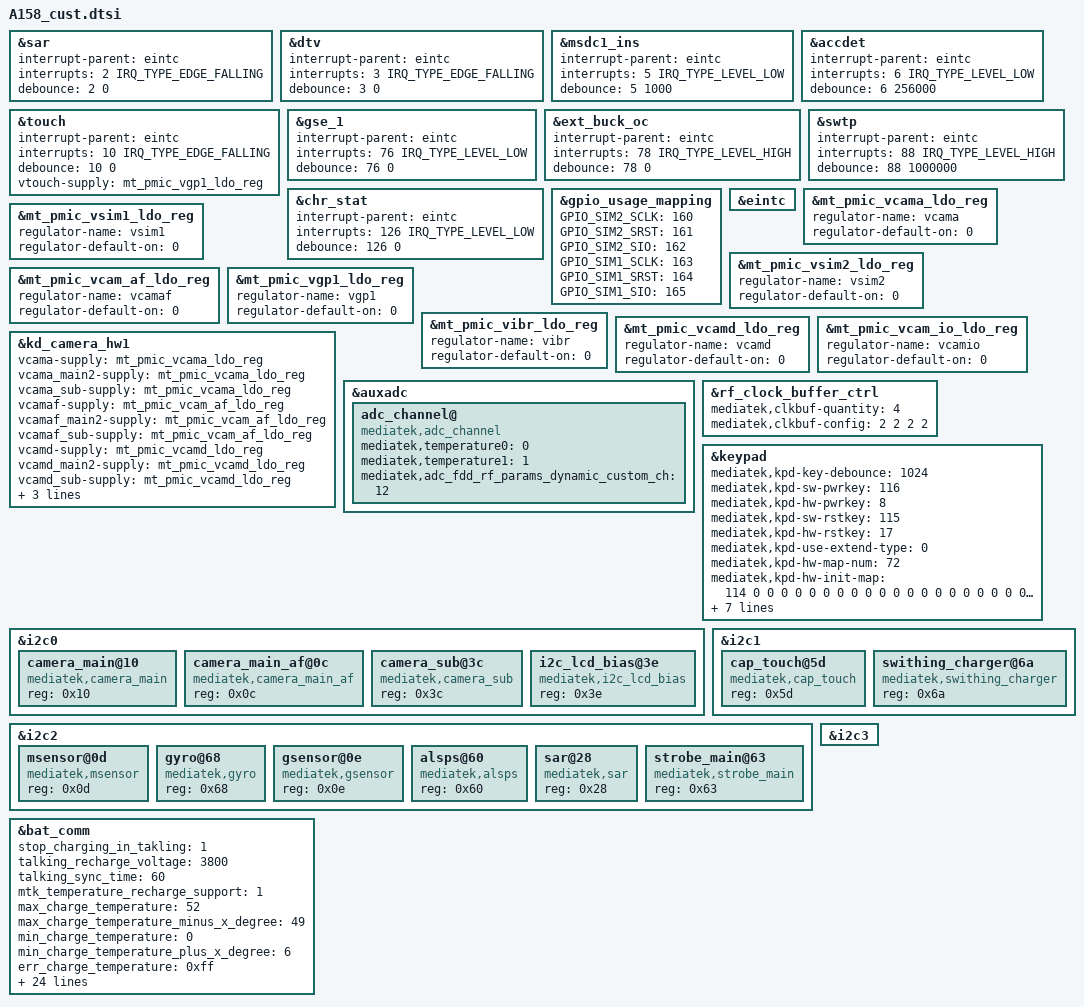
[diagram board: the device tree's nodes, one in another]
/*
 * Generated by MTK SP Drv_CodeGen Version 03.13.6  for MT6735M. Copyright MediaTek Inc. (C) 2013.
 * Fri Jun  1 13:42:01 2018
 * Do Not Modify the File.
 */

#include <dt-bindings/interrupt-controller/irq.h>
#include <dt-bindings/interrupt-controller/arm-gic.h>

/*************************
 * EINT DTSI File
*************************/

&sar {
	interrupt-parent = <&eintc>;
	interrupts = <2 IRQ_TYPE_EDGE_FALLING>;
	debounce = <2 0>;
	status = "okay";
};
&dtv {
	interrupt-parent = <&eintc>;
	interrupts = <3 IRQ_TYPE_EDGE_FALLING>;
	debounce = <3 0>;
	status = "okay";
};
&msdc1_ins {
	interrupt-parent = <&eintc>;
	interrupts = <5 IRQ_TYPE_LEVEL_LOW>;
	debounce = <5 1000>;
	status = "okay";
};
&accdet {
	interrupt-parent = <&eintc>;
	interrupts = <6 IRQ_TYPE_LEVEL_LOW>;
	debounce = <6 256000>;
	status = "okay";
};
&touch {
	interrupt-parent = <&eintc>;
	interrupts = <10 IRQ_TYPE_EDGE_FALLING>;
	debounce = <10 0>;
	status = "okay";
};
&gse_1 {
	interrupt-parent = <&eintc>;
	interrupts = <76 IRQ_TYPE_LEVEL_LOW>;
	debounce = <76 0>;
	status = "okay";
};
&ext_buck_oc {
	interrupt-parent = <&eintc>;
	interrupts = <78 IRQ_TYPE_LEVEL_HIGH>;
	debounce = <78 0>;
	status = "okay";
};
&swtp {
	interrupt-parent = <&eintc>;
	interrupts = <88 IRQ_TYPE_LEVEL_HIGH>;
	debounce = <88 1000000>;
	status = "okay";
};
&chr_stat {
	interrupt-parent = <&eintc>;
	interrupts = <126 IRQ_TYPE_LEVEL_LOW>;
	debounce = <126 0>;
	status = "okay";
};


/********************
 * GPIO USAGE MAPPING DTSI File
****************/

&gpio_usage_mapping {
	GPIO_SIM2_SCLK = <160>;
	GPIO_SIM2_SRST = <161>;
	GPIO_SIM2_SIO = <162>;
	GPIO_SIM1_SCLK = <163>;
	GPIO_SIM1_SRST = <164>;
	GPIO_SIM1_SIO = <165>;
};


&eintc {
};


/*************************
 * PMIC DTSI File
*************************/

&mt_pmic_vcama_ldo_reg {
	regulator-name = "vcama";
	regulator-default-on = <0>; /* 0:skip, 1: off, 2:on */
	status = "okay";
};
&mt_pmic_vsim1_ldo_reg {
	regulator-name = "vsim1";
	regulator-default-on = <0>; /* 0:skip, 1: off, 2:on */
	status = "okay";
};
&mt_pmic_vsim2_ldo_reg {
	regulator-name = "vsim2";
	regulator-default-on = <0>; /* 0:skip, 1: off, 2:on */
	status = "okay";
};
&mt_pmic_vcam_af_ldo_reg {
	regulator-name = "vcamaf";
	regulator-default-on = <0>; /* 0:skip, 1: off, 2:on */
	status = "okay";
};
&mt_pmic_vgp1_ldo_reg {
	regulator-name = "vgp1";
	regulator-default-on = <0>; /* 0:skip, 1: off, 2:on */
	status = "okay";
};
&mt_pmic_vibr_ldo_reg {
	regulator-name = "vibr";
	regulator-default-on = <0>; /* 0:skip, 1: off, 2:on */
	status = "okay";
};
&mt_pmic_vcamd_ldo_reg {
	regulator-name = "vcamd";
	regulator-default-on = <0>; /* 0:skip, 1: off, 2:on */
	status = "okay";
};
&mt_pmic_vcam_io_ldo_reg {
	regulator-name = "vcamio";
	regulator-default-on = <0>; /* 0:skip, 1: off, 2:on */
	status = "okay";
};

&kd_camera_hw1 {
	vcama-supply = <&mt_pmic_vcama_ldo_reg>;
	vcama_main2-supply = <&mt_pmic_vcama_ldo_reg>;
	vcama_sub-supply = <&mt_pmic_vcama_ldo_reg>;

	vcamaf-supply = <&mt_pmic_vcam_af_ldo_reg>;
	vcamaf_main2-supply = <&mt_pmic_vcam_af_ldo_reg>;
	vcamaf_sub-supply = <&mt_pmic_vcam_af_ldo_reg>;

	vcamd-supply = <&mt_pmic_vcamd_ldo_reg>;
	vcamd_main2-supply = <&mt_pmic_vcamd_ldo_reg>;
	vcamd_sub-supply = <&mt_pmic_vcamd_ldo_reg>;

	vcamio-supply = <&mt_pmic_vcam_io_ldo_reg>;
	vcamio_main2-supply = <&mt_pmic_vcam_io_ldo_reg>;
	vcamio_sub-supply = <&mt_pmic_vcam_io_ldo_reg>;

	status = "okay";
};

&touch {
	vtouch-supply = <&mt_pmic_vgp1_ldo_reg>;
	status = "okay";
};


/********************************************
 *ADC DTSI File
********************************************/

&auxadc {
	adc_channel@ {
		compatible = "mediatek,adc_channel";
		mediatek,temperature0 = <0>;
		mediatek,temperature1 = <1>;
		mediatek,adc_fdd_rf_params_dynamic_custom_ch = <12>;
		status = "okay";
	};
};


/**********************************************
 *CLK_BUF DTSI File
********************************************/

&rf_clock_buffer_ctrl {
	mediatek,clkbuf-quantity = <4>;
	mediatek,clkbuf-config = <2 2 2 2>;
	status = "okay";
};


/**********************************************
 *Keypad DTSI File
********************************************/

&keypad{
	mediatek,kpd-key-debounce = <1024>;
	mediatek,kpd-sw-pwrkey = <116>;
	mediatek,kpd-hw-pwrkey = <8>;
	mediatek,kpd-sw-rstkey  = <115>;
	mediatek,kpd-hw-rstkey = <17>;
	mediatek,kpd-use-extend-type = <0>;
	/*HW Keycode [0~71] -> Linux Keycode*/
	mediatek,kpd-hw-map-num = <72>;
	mediatek,kpd-hw-init-map = <114 0 0 0 0 0 0 0 0 0 0 0 0 0 0 0 0 0 0 0 0 0 0 0 
				0 0 0 0 0 0 0 0 0 0 0 0 0 0 0 0 0 0 0 0 0 0 0 0 
				0 0 0 0 0 0 0 0 0 0 0 0 0 0 0 0 0 0 0 0 0 0 0 0 >;
	mediatek,kpd-pwrkey-eint-gpio = <0>;
	mediatek,kpd-pwkey-gpio-din  = <0>;
	mediatek,kpd-hw-dl-key0 = <17>;
	mediatek,kpd-hw-dl-key1 = <0>;
	mediatek,kpd-hw-dl-key2 = <8>;
	mediatek,kpd-hw-recovery-key = <17>;
	mediatek,kpd-hw-factory-key = <0>;
	status = "okay";
};


/*************************
 * I2C DTSI File
*************************/

&i2c0 {
	#address-cells = <1>;
	#size-cells = <0>;
	camera_main@10 {
		compatible = "mediatek,camera_main";
		reg = <0x10>;
		status = "okay";
	};
	camera_main_af@0c {
		compatible = "mediatek,camera_main_af";
		reg = <0x0c>;
		status = "okay";
	};
	camera_sub@3c {
		compatible = "mediatek,camera_sub";
		reg = <0x3c>;
		status = "okay";
	};
	i2c_lcd_bias@3e {
		compatible = "mediatek,i2c_lcd_bias";
		reg = <0x3e>;
		status = "okay";
	};
};

&i2c1 {
	#address-cells = <1>;
	#size-cells = <0>;
	cap_touch@5d {
		compatible = "mediatek,cap_touch";
		reg = <0x5d>;
		status = "okay";
	};
	swithing_charger@6a {
		compatible = "mediatek,swithing_charger";
		reg = <0x6a>;
		status = "okay";
	};
};

&i2c2 {
	#address-cells = <1>;
	#size-cells = <0>;
	msensor@0d {
		compatible = "mediatek,msensor";
		reg = <0x0d>;
		status = "okay";
	};
	gyro@68 {
		compatible = "mediatek,gyro";
		reg = <0x68>;
		status = "okay";
	};
	gsensor@0e {
		compatible = "mediatek,gsensor";
		reg = <0x0e>;
		status = "okay";
	};
	alsps@60 {
		compatible = "mediatek,alsps";
		reg = <0x60>;
		status = "okay";
	};
	sar@28 {
		compatible = "mediatek,sar";
		reg = <0x28>;
		status = "okay";
	};
	strobe_main@63 {
		compatible = "mediatek,strobe_main";
		reg = <0x63>;
		status = "okay";
	};
};

&i2c3 {
	#address-cells = <1>;
	#size-cells = <0>;
};

&bat_comm {
			/* cust_charging.h */
			/* stop charging while in talking mode */
			stop_charging_in_takling = <1 >;
			talking_recharge_voltage = <3800 >;
			talking_sync_time = <60 >;

			/* Battery Temperature Protection */
			mtk_temperature_recharge_support = <1 >;
			max_charge_temperature = <52 >;
			max_charge_temperature_minus_x_degree = <49 >;
			min_charge_temperature = <0 >;
			min_charge_temperature_plus_x_degree = <6 >;
			err_charge_temperature = <0xff >;

			/* Linear Charging Threshold */
			v_pre2cc_thres = <3400 >;	/* unit: mV */
			v_cc2topoff_thres = <4050 >;
			recharging_voltage = <4110 >;
			charging_full_current = <100 >;	/* unit: mA */

			/* Charging Current Setting */
			config_usb_if = <0 >;
			usb_charger_current_suspend = <0 >;	/* Unit: 0.01 mA */
			usb_charger_current_unconfigured = <7000 >;	/* Unit: 0.01 mA */
			usb_charger_current_configured = <50000 >;	/* Unit: 0.01 mA */
			usb_charger_current = <50000 >;	/* Unit: 0.01 mA */
			ac_charger_current = <125000 >;	/* Unit: 0.01 mA */
			non_std_ac_charger_current = <125000 >;	/* Unit: 0.01 mA */
			charging_host_charger_current = <65000 >;	/* Unit: 0.01 mA */
			apple_0_5a_charger_current = <50000 >;	/* Unit: 0.01 mA */
			apple_1_0a_charger_current = <65000 >;	/* Unit: 0.01 mA */
			apple_2_1a_charger_current = <80000 >;	/* Unit: 0.01 mA */

			/* charger error check */
			bat_low_temp_protect_enable = <1 >;/*qiantao@wind-mobi.com*/
			v_charger_enable = <1 >;	/* 1:on , 0:off */
			v_charger_max = <6500 >;	/* unit: mV */
			v_charger_min = <4400 >;

			/*  Tracking TIME */
			onehundred_percent_tracking_time = <10 >;	/* Unit: second */
			npercent_tracking_time = <20 >;	/* Unit: second */
			sync_to_real_tracking_time = <60 >;	/* Unit: second */
			v_0percent_tracking = <3450 >;	/* Unit: mV */

			/* High battery support */
			high_battery_voltage_support = <1>;
		};
